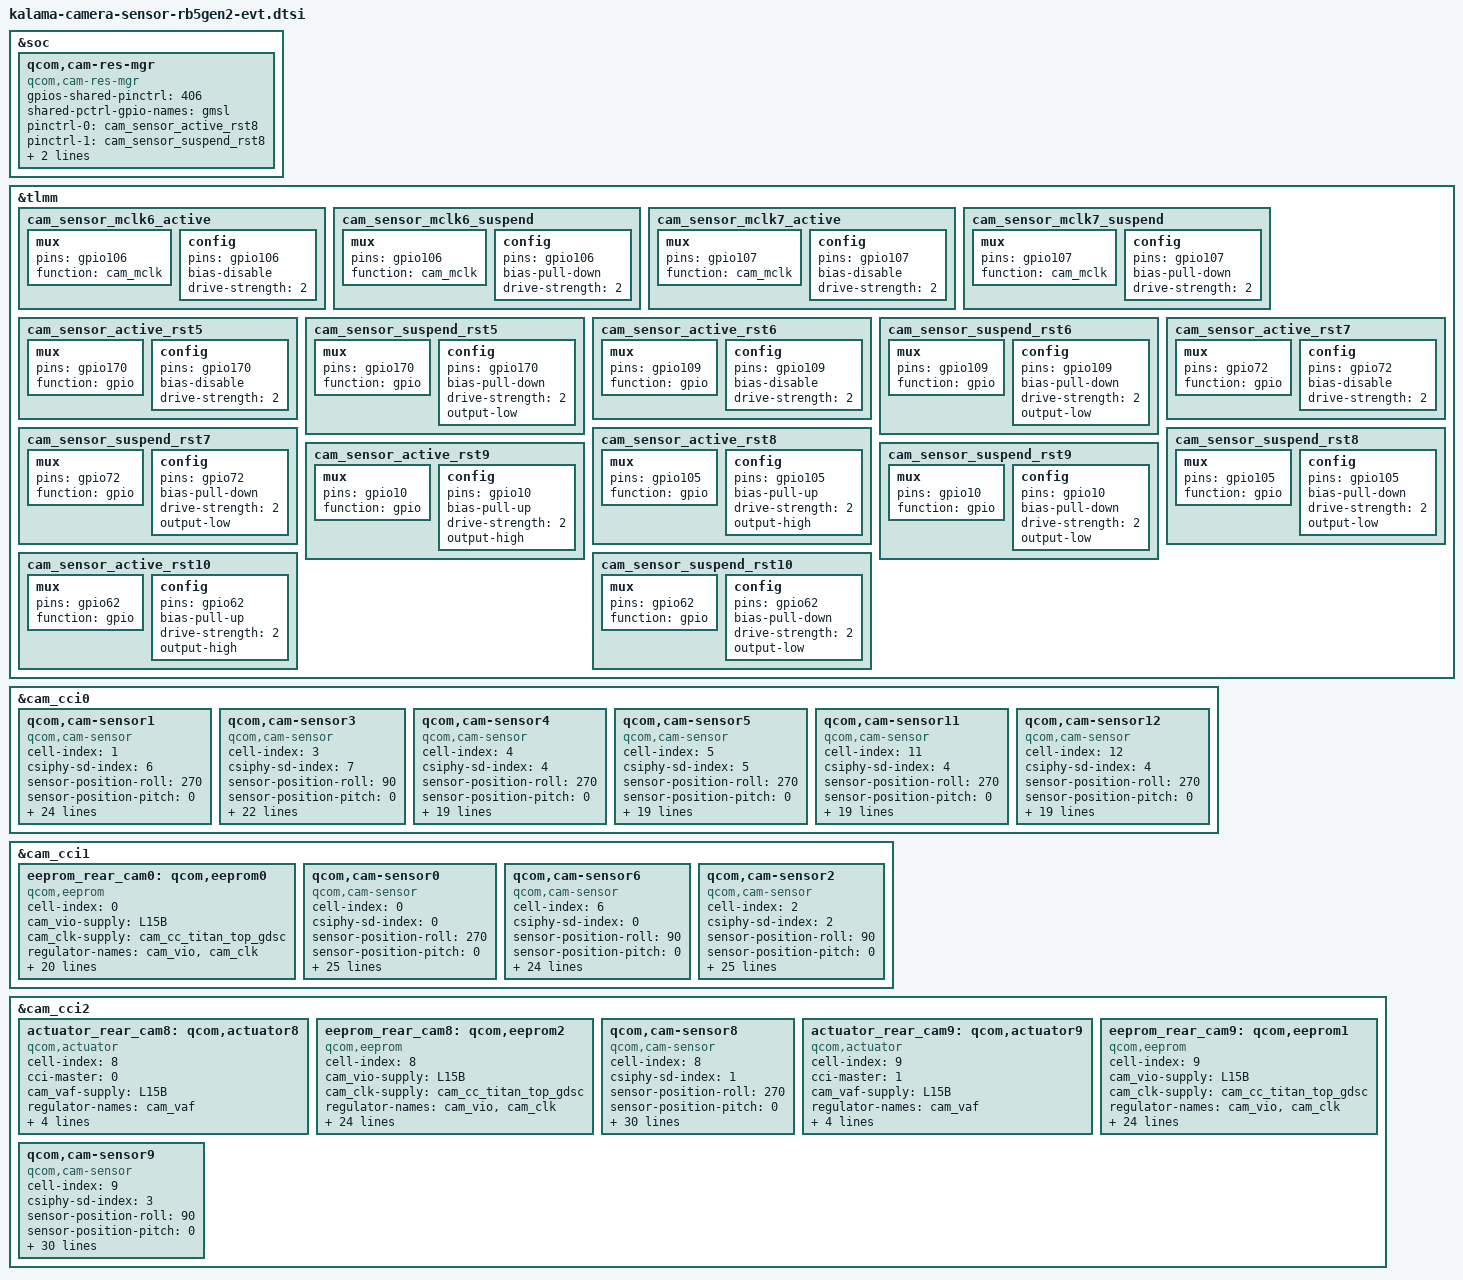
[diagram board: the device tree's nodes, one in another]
#include <dt-bindings/msm-camera.h>

&soc {
    qcom,cam-res-mgr {
        compatible = "qcom,cam-res-mgr";
        status = "ok";
        gpios-shared-pinctrl = <406>;
        shared-pctrl-gpio-names = "gmsl";
        pinctrl-names = "gmsl_active", "gmsl_suspend",
                        "mclk0_active", "mclk0_suspend";
        pinctrl-0 = <&cam_sensor_active_rst8>;
        pinctrl-1 = <&cam_sensor_suspend_rst8>;
        pinctrl-2 = <&cam_sensor_mclk0_active>;
        pinctrl-3 = <&cam_sensor_mclk0_suspend>;
    };
};

&tlmm {
    cam_sensor_mclk6_active: cam_sensor_mclk6_active {
        /* MCLK6 */
        mux {
            pins = "gpio106";
            function = "cam_mclk";
        };

        config {
            pins = "gpio106";
            bias-disable; /* No PULL */
            drive-strength = <2>; /* 2 MA */
        };
    };

    cam_sensor_mclk6_suspend: cam_sensor_mclk6_suspend {
        /* MCLK6 */
        mux {
            pins = "gpio106";
            function = "cam_mclk";
        };

        config {
            pins = "gpio106";
            bias-pull-down; /* PULL DOWN */
            drive-strength = <2>; /* 2 MA */
        };
    };

    cam_sensor_mclk7_active: cam_sensor_mclk7_active {
        /* MCLK7 */
        mux {
            pins = "gpio107";
            function = "cam_mclk";
        };

        config {
            pins = "gpio107";
            bias-disable; /* No PULL */
            drive-strength = <2>; /* 2 MA */
        };
    };

    cam_sensor_mclk7_suspend: cam_sensor_mclk7_suspend {
        /* MCLK7 */
        mux {
            pins = "gpio107";
            function = "cam_mclk";
        };

        config {
            pins = "gpio107";
            bias-pull-down; /* PULL DOWN */
            drive-strength = <2>; /* 2 MA */
        };
    };

    cam_sensor_active_rst5: cam_sensor_active_rst5 {
        mux {
            pins = "gpio170";
            function = "gpio";
        };

        config {
            pins = "gpio170";
            bias-disable; /* No PULL */
            drive-strength = <2>; /* 2 MA */
        };
    };

    cam_sensor_suspend_rst5: cam_sensor_suspend_rst5 {
        mux {
            pins = "gpio170";
            function = "gpio";
        };

        config {
            pins = "gpio170";
            bias-pull-down; /* PULL DOWN */
            drive-strength = <2>; /* 2 MA */
            output-low;
        };
    };

    cam_sensor_active_rst6: cam_sensor_active_rst6 {
        mux {
            pins = "gpio109";
            function = "gpio";
        };

        config {
            pins = "gpio109";
            bias-disable; /* No PULL */
            drive-strength = <2>; /* 2 MA */
        };
    };

    cam_sensor_suspend_rst6: cam_sensor_suspend_rst6 {
        mux {
            pins = "gpio109";
            function = "gpio";
        };

        config {
            pins = "gpio109";
            bias-pull-down; /* PULL DOWN */
            drive-strength = <2>; /* 2 MA */
            output-low;
        };
    };

    cam_sensor_active_rst7: cam_sensor_active_rst7 {
        mux {
            pins = "gpio72";
            function = "gpio";
        };

        config {
            pins = "gpio72";
            bias-disable; /* No PULL */
            drive-strength = <2>; /* 2 MA */
        };
    };

    cam_sensor_suspend_rst7: cam_sensor_suspend_rst7 {
        mux {
            pins = "gpio72";
            function = "gpio";
        };

        config {
            pins = "gpio72";
            bias-pull-down; /* PULL DOWN */
            drive-strength = <2>; /* 2 MA */
            output-low;
        };
    };

    cam_sensor_active_rst8: cam_sensor_active_rst8 {
        /* RESET */
        mux {
            pins = "gpio105";
            function = "gpio";
        };

        config {
            pins = "gpio105";
            bias-pull-up;
            drive-strength = <2>; /* 2 MA */
            output-high;
        };
    };

    cam_sensor_suspend_rst8: cam_sensor_suspend_rst8 {
        /* RESET */
        mux {
            pins = "gpio105";
            function = "gpio";
        };

        config {
            pins = "gpio105";
            bias-pull-down; /* PULL DOWN */
            drive-strength = <2>; /* 2 MA */
            output-low;
        };
    };

    cam_sensor_active_rst9: cam_sensor_active_rst9 {
        /* RESET */
        mux {
            pins = "gpio10";
            function = "gpio";
        };

        config {
            pins = "gpio10";
            bias-pull-up;
            drive-strength = <2>; /* 2 MA */
            output-high;
        };
    };

    cam_sensor_suspend_rst9: cam_sensor_suspend_rst9 {
        /* RESET */
        mux {
            pins = "gpio10";
            function = "gpio";
        };

        config {
            pins = "gpio10";
            bias-pull-down; /* PULL DOWN */
            drive-strength = <2>; /* 2 MA */
            output-low;
        };
    };

    cam_sensor_active_rst10: cam_sensor_active_rst10 {
        /* RESET */
        mux {
            pins = "gpio62";
            function = "gpio";
        };

        config {
            pins = "gpio62";
            bias-pull-up;
            drive-strength = <2>; /* 2 MA */
            output-high;
        };
    };

    cam_sensor_suspend_rst10: cam_sensor_suspend_rst10 {
        /* RESET */
        mux {
            pins = "gpio62";
            function = "gpio";
        };

        config {
            pins = "gpio62";
            bias-pull-down; /* PULL DOWN */
            drive-strength = <2>; /* 2 MA */
            output-low;
        };
    };
};

&cam_cci0 {
    /*CAM 1*/
    qcom,cam-sensor1 {
        cell-index = <1>;
        compatible = "qcom,cam-sensor";
        csiphy-sd-index = <6>;
        sensor-position-roll = <270>;
        sensor-position-pitch = <0>;
        sensor-position-yaw = <0>;
        cam_vio-supply = <&L15B>;
        cam_clk-supply = <&cam_cc_titan_top_gdsc>;
        regulator-names = "cam_vio", "cam_clk";
        rgltr-cntrl-support;
        pwm-switch;
        rgltr-min-voltage = <1800000 0>;
        rgltr-max-voltage = <1800000 0>;
        rgltr-load-current = <120000 0>;
        gpio-no-mux = <0>;
        pinctrl-names = "cam_default", "cam_suspend";
        pinctrl-0 = <&cam_sensor_mclk1_active
                 &cam_sensor_active_rst1>;
        pinctrl-1 = <&cam_sensor_mclk1_suspend
                 &cam_sensor_suspend_rst1>;
        gpios = <&tlmm 101 0>,
            <&tlmm 117 0>;
        gpio-reset = <1>;
        gpio-req-tbl-num = <0 1>;
        gpio-req-tbl-flags = <1 0>;
        gpio-req-tbl-label = "CAMIF_MCLK1",
                    "CAM_RESET1";
        sensor-mode = <0>;
        cci-master = <1>;
        status = "ok";
        clocks = <&camcc CAM_CC_MCLK1_CLK>;
        clock-names = "cam_clk";
        clock-cntl-level = "turbo";
        clock-rates = <24000000>;
    };

    /*CAM 3*/
    qcom,cam-sensor3 {
        cell-index = <3>;
        compatible = "qcom,cam-sensor";
        csiphy-sd-index = <7>;
        sensor-position-roll = <90>;
        sensor-position-pitch = <0>;
        sensor-position-yaw = <180>;
        cam_vio-supply = <&L15B>;
        cam_clk-supply = <&cam_cc_titan_top_gdsc>;
        regulator-names = "cam_vio", "cam_clk";
        rgltr-cntrl-support;
        rgltr-min-voltage = <1800000 0>;
        rgltr-max-voltage = <1800000 0>;
        rgltr-load-current = <120000 0>;
        gpio-no-mux = <0>;
        pinctrl-names = "cam_default", "cam_suspend";
        pinctrl-0 = <&cam_sensor_mclk3_active
                &cam_sensor_active_rst3>;
        pinctrl-1 = <&cam_sensor_mclk3_suspend
                &cam_sensor_suspend_rst3>;
        gpios = <&tlmm 103 0>,
            <&tlmm 119 0>;
        gpio-reset = <1>;
        gpio-req-tbl-num = <0 1>;
        gpio-req-tbl-flags = <1 0>;
        gpio-req-tbl-label = "CAMIF_MCLK3",
                    "CAM_RESET3";
        cci-master = <0>;
        status = "ok";
        clocks = <&camcc CAM_CC_MCLK3_CLK>;
        clock-names = "cam_clk";
        clock-cntl-level = "nominal";
        clock-rates = <24000000>;
    };

    /*GMSL 1*/
    qcom,cam-sensor4 {
        cell-index = <4>;
        compatible = "qcom,cam-sensor";
        csiphy-sd-index = <4>;
        sensor-position-roll = <270>;
        sensor-position-pitch = <0>;
        sensor-position-yaw = <0>;
        cam_vio-supply = <&L15B>;
        cam_clk-supply = <&cam_cc_titan_top_gdsc>;
        regulator-names = "cam_vio", "cam_clk";
        rgltr-cntrl-support;
        pwm-switch;
        rgltr-min-voltage = <1800000 0>;
        rgltr-max-voltage = <1800000 0>;
        rgltr-load-current = <120000 0>;
        gpio-no-mux = <0>;
        pinctrl-names = "cam_default", "cam_suspend";
        pinctrl-0 = <&cam_sensor_active_rst8>;
        pinctrl-1 = <&cam_sensor_suspend_rst8>;
        gpios = <&tlmm 105 0>;
        gpio-reset = <0>;
        gpio-req-tbl-num = <0>;
        gpio-req-tbl-flags = <0>;
        gpio-req-tbl-label = "CAM_4";
        sensor-mode = <0>;
        cci-master = <0>;
        status = "ok";
     };

    /*GMSL 2*/
    qcom,cam-sensor5 {
        cell-index = <5>;
        compatible = "qcom,cam-sensor";
        csiphy-sd-index = <5>;
        sensor-position-roll = <270>;
        sensor-position-pitch = <0>;
        sensor-position-yaw = <0>;
        cam_vio-supply = <&L15B>;
        cam_clk-supply = <&cam_cc_titan_top_gdsc>;
        regulator-names = "cam_vio", "cam_clk";
        rgltr-cntrl-support;
        pwm-switch;
        rgltr-min-voltage = <1800000 0>;
        rgltr-max-voltage = <1800000 0>;
        rgltr-load-current = <120000 0>;
        gpio-no-mux = <0>;
        pinctrl-names = "cam_default", "cam_suspend";
        pinctrl-0 = <&cam_sensor_active_rst8>;
        pinctrl-1 = <&cam_sensor_suspend_rst8>;
        gpios = <&tlmm 105 0>;
        gpio-reset = <0>;
        gpio-req-tbl-num = <0>;
        gpio-req-tbl-flags = <0>;
        gpio-req-tbl-label = "CAM_5";
        sensor-mode = <0>;
        cci-master = <0>;
        status = "ok";
    };

    /*GMSL 3*/
    qcom,cam-sensor11 {
        cell-index = <11>;
        compatible = "qcom,cam-sensor";
        csiphy-sd-index = <4>;
        sensor-position-roll = <270>;
        sensor-position-pitch = <0>;
        sensor-position-yaw = <0>;
        cam_vio-supply = <&L15B>;
        cam_clk-supply = <&cam_cc_titan_top_gdsc>;
        regulator-names = "cam_vio", "cam_clk";
        rgltr-cntrl-support;
        pwm-switch;
        rgltr-min-voltage = <1800000 0>;
        rgltr-max-voltage = <1800000 0>;
        rgltr-load-current = <120000 0>;
        gpio-no-mux = <0>;
        pinctrl-names = "cam_default", "cam_suspend";
        pinctrl-0 = <&cam_sensor_active_rst8>;
        pinctrl-1 = <&cam_sensor_suspend_rst8>;
        gpios = <&tlmm 105 0>;
        gpio-reset = <0>;
        gpio-req-tbl-num = <0>;
        gpio-req-tbl-flags = <0>;
        gpio-req-tbl-label = "CAM_11";
        sensor-mode = <0>;
        cci-master = <0>;
        status = "ok";
    };

    /*GMSL 4*/
    qcom,cam-sensor12 {
        cell-index = <12>;
        compatible = "qcom,cam-sensor";
        csiphy-sd-index = <4>;
        sensor-position-roll = <270>;
        sensor-position-pitch = <0>;
        sensor-position-yaw = <0>;
        cam_vio-supply = <&L15B>;
        cam_clk-supply = <&cam_cc_titan_top_gdsc>;
        regulator-names = "cam_vio", "cam_clk";
        rgltr-cntrl-support;
        pwm-switch;
        rgltr-min-voltage = <1800000 0>;
        rgltr-max-voltage = <1800000 0>;
        rgltr-load-current = <120000 0>;
        gpio-no-mux = <0>;
        pinctrl-names = "cam_default", "cam_suspend";
        pinctrl-0 = <&cam_sensor_active_rst8>;
        pinctrl-1 = <&cam_sensor_suspend_rst8>;
        gpios = <&tlmm 105 0>;
        gpio-reset = <0>;
        gpio-req-tbl-num = <0>;
        gpio-req-tbl-flags = <0>;
        gpio-req-tbl-label = "CAM_12";
        sensor-mode = <0>;
        cci-master = <0>;
        status = "ok";
    };
};

&cam_cci1 {
    eeprom_rear_cam0: qcom,eeprom0 {
        cell-index = <0>;
        compatible = "qcom,eeprom";
        cam_vio-supply = <&L15B>;
        cam_clk-supply = <&cam_cc_titan_top_gdsc>;
        regulator-names = "cam_vio", "cam_clk";
        rgltr-cntrl-support;
        pwm-switch;
        rgltr-min-voltage = <1800000 0>;
        rgltr-max-voltage = <1800000 0>;
        rgltr-load-current = <120000 0>;
        gpio-no-mux = <0>;
        pinctrl-names = "cam_default", "cam_suspend";
        pinctrl-0 = <&cam_sensor_mclk2_active
                 &cam_sensor_active_rst2>;
        pinctrl-1 = <&cam_sensor_mclk2_suspend
                 &cam_sensor_suspend_rst2>;
        gpios = <&tlmm 96 0>,
            <&tlmm 78 0>;
        gpio-reset = <1>;
        gpio-req-tbl-num = <0 1>;
        gpio-req-tbl-flags = <1 0>;
        gpio-req-tbl-label = "CAMIF_MCLK2",
                    "CAM_RESET2";
        sensor-mode = <0>;
        cci-master = <0>;
        status = "ok";
        clocks = <&camcc CAM_CC_MCLK2_CLK>;
        clock-names = "cam_clk";
        clock-cntl-level = "turbo";
        clock-rates = <24000000>;
    };

    /*CAM 0A*/
    qcom,cam-sensor0 {
        cell-index = <0>;
        compatible = "qcom,cam-sensor";
        csiphy-sd-index = <0>;
        sensor-position-roll = <270>;
        sensor-position-pitch = <0>;
        sensor-position-yaw = <0>;
        eeprom-src = <&eeprom_rear_cam0>;
        cam_vio-supply = <&L15B>;
        cam_clk-supply = <&cam_cc_titan_top_gdsc>;
        regulator-names = "cam_vio", "cam_clk";
        rgltr-cntrl-support;
        pwm-switch;
        rgltr-min-voltage = <1800000 0>;
        rgltr-max-voltage = <1800000 0>;
        rgltr-load-current = <120000 0>;
        gpio-no-mux = <0>;
        pinctrl-names = "cam_default", "cam_suspend";
        pinctrl-0 = <&cam_sensor_mclk0_active
                 &cam_sensor_active_rst0>;
        pinctrl-1 = <&cam_sensor_mclk0_suspend
                 &cam_sensor_suspend_rst0>;
        gpios = <&tlmm 100 0>,
            <&tlmm 116 0>;
        gpio-reset = <1>;
        gpio-req-tbl-num = <0 1>;
        gpio-req-tbl-flags = <1 0>;
        gpio-req-tbl-label = "CAMIF_MCLK0",
                    "CAM_RESET0";
        sensor-mode = <0>;
        cci-master = <1>;
        status = "ok";
        clocks = <&camcc CAM_CC_MCLK0_CLK>;
        clock-names = "cam_clk";
        clock-cntl-level = "turbo";
        clock-rates = <24000000>;
    };

    /*CAM 0B*/
    qcom,cam-sensor6 {
        cell-index = <6>;
        compatible = "qcom,cam-sensor";
        csiphy-sd-index = <0>;
        sensor-position-roll = <90>;
        sensor-position-pitch = <0>;
        sensor-position-yaw = <180>;
        cam_vio-supply = <&L15B>;
        cam_clk-supply = <&cam_cc_titan_top_gdsc>;
        regulator-names = "cam_vio", "cam_clk";
        rgltr-cntrl-support;
        pwm-switch;
        rgltr-min-voltage = <1800000 0>;
        rgltr-max-voltage = <1800000 0>;
        rgltr-load-current = <120000 0>;
        gpio-no-mux = <0>;
        pinctrl-names = "cam_default", "cam_suspend";
        pinctrl-0 = <&cam_sensor_mclk0_active
                 &cam_sensor_active_rst4>;
        pinctrl-1 = <&cam_sensor_mclk0_suspend
                 &cam_sensor_suspend_rst4>;
        gpios = <&tlmm 100 0>,
            <&tlmm 120 0>;
        gpio-reset = <1>;
        gpio-req-tbl-num = <0 1>;
        gpio-req-tbl-flags = <1 0>;
        gpio-req-tbl-label = "CAMIF_MCLK0",
                    "CAM_RESET0";
        sensor-mode = <0>;
        cci-master = <0>;
        status = "ok";
        clocks = <&camcc CAM_CC_MCLK0_CLK>;
        clock-names = "cam_clk";
        clock-cntl-level = "turbo";
        clock-rates = <24000000>;
    };

    /*CAM 2*/
    qcom,cam-sensor2 {
        cell-index = <2>;
        compatible = "qcom,cam-sensor";
        csiphy-sd-index = <2>;
        sensor-position-roll = <90>;
        sensor-position-pitch = <0>;
        sensor-position-yaw = <180>;
        eeprom-src = <&eeprom_rear_cam0>;
        cam_vio-supply = <&L15B>;
        cam_clk-supply = <&cam_cc_titan_top_gdsc>;
        regulator-names = "cam_vio", "cam_clk";
        rgltr-cntrl-support;
        pwm-switch;
        rgltr-min-voltage = <1800000 0>;
        rgltr-max-voltage = <1800000 0>;
        rgltr-load-current = <120000 0>;
        gpio-no-mux = <0>;
        pinctrl-names = "cam_default", "cam_suspend";
        pinctrl-0 = <&cam_sensor_mclk2_active
            &cam_sensor_active_rst2>;
        pinctrl-1 = <&cam_sensor_mclk2_suspend
            &cam_sensor_suspend_rst2>;
        gpios = <&tlmm 102 0>,
            <&tlmm 118 0>;
        gpio-reset = <1>;
        gpio-req-tbl-num = <0 1>;
        gpio-req-tbl-flags = <1 0>;
        gpio-req-tbl-label = "CAMIF_MCLK2",
                "CAM_RESET2";
        sensor-mode = <0>;
        cci-master = <0>;
        status = "ok";
        clocks = <&camcc CAM_CC_MCLK2_CLK>;
        clock-names = "cam_clk";
        clock-cntl-level = "turbo";
        clock-rates = <24000000>;
    };
};

&cam_cci2 {

    actuator_rear_cam8: qcom,actuator8 {
        cell-index = <8>;
        compatible = "qcom,actuator";
        cci-master = <0>;
        cam_vaf-supply = <&L15B>;
        regulator-names = "cam_vaf";
        rgltr-cntrl-support;
        rgltr-min-voltage = <1800000>;
        rgltr-max-voltage = <1800000>;
        rgltr-load-current = <120000>;
    };

    eeprom_rear_cam8: qcom,eeprom2 {
        cell-index = <8>;
        compatible = "qcom,eeprom";
        cam_vio-supply = <&L15B>;
        cam_clk-supply = <&cam_cc_titan_top_gdsc>;
        regulator-names = "cam_vio", "cam_clk";
        rgltr-cntrl-support;
        pwm-switch;
        rgltr-min-voltage = <1800000 0>;
        rgltr-max-voltage = <1800000 0>;
        rgltr-load-current = <120000 0>;
        gpio-no-mux = <0>;
        pinctrl-names = "cam_default", "cam_suspend";
        pinctrl-0 = <&cam_sensor_mclk6_active
                 &cam_sensor_active_rst6
                 &cam_sensor_active_rst9>;
        pinctrl-1 = <&cam_sensor_mclk6_suspend
                 &cam_sensor_suspend_rst6
                 &cam_sensor_suspend_rst9>;
        gpios = <&tlmm 106 0>,
                <&tlmm 109 0>,
                <&tlmm 10 0>;
        gpio-reset = <1>;
        gpio-standby = <2>;
        gpio-req-tbl-num = <0 1 2>;
        gpio-req-tbl-flags = <1 0 0>;
        gpio-req-tbl-label = "CAMIF_MCLK6",
                    "CAM_RESET6",
                    "CAM_STANDBY";
        sensor-mode = <0>;
        cci-master = <0>;
        status = "ok";
        clocks = <&camcc CAM_CC_MCLK6_CLK>;
        clock-names = "cam_clk";
        clock-cntl-level = "turbo";
        clock-rates = <24000000>;
    };

    qcom,cam-sensor8 {
        cell-index = <8>;
        compatible = "qcom,cam-sensor";
        csiphy-sd-index = <1>;
        sensor-position-roll = <270>;
        sensor-position-pitch = <0>;
        sensor-position-yaw = <0>;
        actuator-src = <&actuator_rear_cam8>;
        eeprom-src = <&eeprom_rear_cam8>;
        cam_vio-supply = <&L15B>;

        cam_clk-supply = <&cam_cc_titan_top_gdsc>;
        regulator-names = "cam_vio",  "cam_clk";
        rgltr-cntrl-support;
        pwm-switch;
        rgltr-min-voltage = <1800000 0>;
        rgltr-max-voltage = <1800000 0>;
        rgltr-load-current = <120000 0>;
        gpio-no-mux = <0>;
        pinctrl-names = "cam_default", "cam_suspend";
        pinctrl-0 = <&cam_sensor_mclk6_active
                 &cam_sensor_active_rst6
                 &cam_sensor_active_rst9>;
        pinctrl-1 = <&cam_sensor_mclk6_suspend
                 &cam_sensor_suspend_rst6
                 &cam_sensor_suspend_rst9>;
        gpios = <&tlmm 106 0>,
                <&tlmm 109 0>,
                <&tlmm 10 0>;
        gpio-reset = <1>;
        gpio-standby = <2>;
        gpio-req-tbl-num = <0 1 2>;
        gpio-req-tbl-flags = <1 0 0>;
        gpio-req-tbl-label = "CAMIF_MCLK6",
                    "CAM_RESET6",
                    "CAM_STANDBY";
        sensor-mode = <0>;
        cci-master = <0>;
        status = "ok";
        clocks = <&camcc CAM_CC_MCLK6_CLK>;
        clock-names = "cam_clk";
        clock-cntl-level = "turbo";
        clock-rates = <24000000>;
    };

    actuator_rear_cam9: qcom,actuator9 {
        cell-index = <9>;
        compatible = "qcom,actuator";
        cci-master = <1>;
        cam_vaf-supply = <&L15B>;
        regulator-names = "cam_vaf";
        rgltr-cntrl-support;
        rgltr-min-voltage = <1800000>;
        rgltr-max-voltage = <1800000>;
        rgltr-load-current = <120000>;
    };

    eeprom_rear_cam9: qcom,eeprom1 {
        cell-index = <9>;
        compatible = "qcom,eeprom";
        cam_vio-supply = <&L15B>;
        cam_clk-supply = <&cam_cc_titan_top_gdsc>;
        regulator-names = "cam_vio", "cam_clk";
        rgltr-cntrl-support;
        pwm-switch;
        rgltr-min-voltage = <1800000 0>;
        rgltr-max-voltage = <1800000 0>;
        rgltr-load-current = <120000 0>;
        gpio-no-mux = <0>;
        pinctrl-names = "cam_default", "cam_suspend";
        pinctrl-0 = <&cam_sensor_mclk7_active
                 &cam_sensor_active_rst7
                 &cam_sensor_active_rst10>;
        pinctrl-1 = <&cam_sensor_mclk7_suspend
                 &cam_sensor_suspend_rst7
                 &cam_sensor_suspend_rst10>;
        gpios = <&tlmm 107 0>,
            <&tlmm 72 0>,
            <&tlmm 62 0> ;
        gpio-reset = <1>;
        gpio-standby = <2>;
        gpio-req-tbl-num = <0 1 2>;
        gpio-req-tbl-flags = <1 0 0>;
        gpio-req-tbl-label = "CAMIF_MCLK7",
                    "CAM_RESET7",
                    "CAM_STANDBY";
        sensor-mode = <0>;
        cci-master = <1>;
        status = "ok";
        clocks = <&camcc CAM_CC_MCLK7_CLK>;
        clock-names = "cam_clk";
        clock-cntl-level = "turbo";
        clock-rates = <24000000>;
    };

    qcom,cam-sensor9 {
        cell-index = <9>;
        compatible = "qcom,cam-sensor";
        csiphy-sd-index = <3>;
        sensor-position-roll = <90>;
        sensor-position-pitch = <0>;
        sensor-position-yaw = <180>;
        actuator-src = <&actuator_rear_cam9>;
        eeprom-src = <&eeprom_rear_cam9>;
        cam_vio-supply = <&L15B>;
        cam_clk-supply = <&cam_cc_titan_top_gdsc>;
        regulator-names = "cam_vio","cam_clk";
        rgltr-cntrl-support;
        pwm-switch;
        rgltr-min-voltage = <1800000   0>;
        rgltr-max-voltage = <1800000   0>;
        rgltr-load-current = <120000   0>;
        gpio-no-mux = <0>;
        pinctrl-names = "cam_default", "cam_suspend";
        pinctrl-0 = <&cam_sensor_mclk7_active
                 &cam_sensor_active_rst7
                 &cam_sensor_active_rst10>;
        pinctrl-1 = <&cam_sensor_mclk7_suspend
                 &cam_sensor_suspend_rst7
                 &cam_sensor_suspend_rst10>;
        gpios = <&tlmm 107 0>,
            <&tlmm 72 0>,
            <&tlmm 62 0> ;
        gpio-reset = <1>;
        gpio-standby = <2>;
        gpio-req-tbl-num = <0 1 2>;
        gpio-req-tbl-flags = <1 0 0>;
        gpio-req-tbl-label = "CAMIF_MCLK7",
                    "CAM_RESET7",
                    "CAM_STANDBY";
        sensor-mode = <0>;
        cci-master = <1>;
        status = "ok";
        clocks = <&camcc CAM_CC_MCLK7_CLK>;
        clock-names = "cam_clk";
        clock-cntl-level = "turbo";
        clock-rates = <24000000>;
    };
};
